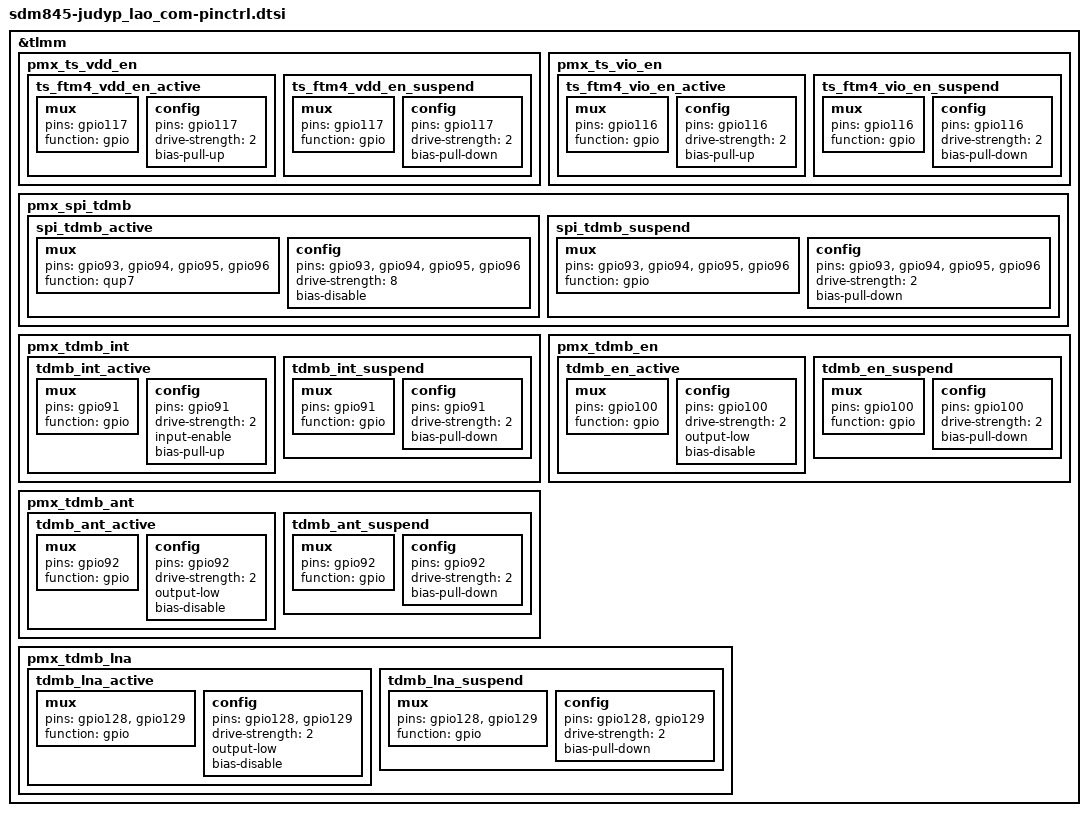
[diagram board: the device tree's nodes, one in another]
/* Copyright (c) 2017, The Linux Foundation. All rights reserved.
 *
 * This program is free software; you can redistribute it and/or modify
 * it under the terms of the GNU General Public License version 2 and
 * only version 2 as published by the Free Software Foundation.
 *
 * This program is distributed in the hope that it will be useful,
 * but WITHOUT ANY WARRANTY; without even the implied warranty of
 * MERCHANTABILITY or FITNESS FOR A PARTICULAR PURPOSE.  See the
 * GNU General Public License for more details.
 */

#include "../sdm845-judyp_common/sdm845-judyp_common-pinctrl.dtsi"

&tlmm {
	       pmx_ts_vdd_en {
			ts_ftm4_vdd_en_active: ts_ftm4_vdd_en_active {
				mux {
					pins = "gpio117";
					function = "gpio";
				};
				config {
					pins = "gpio117";
					drive-strength = <2>;
					bias-pull-up;
				};
			};

			ts_ftm4_vdd_en_suspend: ts_ftm4_vdd_en_suspend {
				mux {
					pins = "gpio117";
					function = "gpio";
				};
				config {
					pins = "gpio117";
					drive-strength = <2>;
					bias-pull-down;
				};
			};
		};

		pmx_ts_vio_en {
			ts_ftm4_vio_en_active: ts_ftm4_vio_en_active {
				mux {
					pins = "gpio116";
					function = "gpio";
				};
				config {
					pins = "gpio116";
					drive-strength = <2>;
					bias-pull-up;
				};
			};

			ts_ftm4_vio_en_suspend: ts_ftm4_vio_en_suspend {
				mux {
					pins = "gpio116";
					function = "gpio";
				};
				config {
					pins = "gpio116";
					drive-strength = <2>;
					bias-pull-down;
				};
			};
		};

	pmx_spi_tdmb {
		spi_tdmb_active: spi_tdmb_active {
			mux {
				pins =  "gpio93", "gpio94", "gpio95", "gpio96";
				function = "qup7";
			};

			config {
				pins =  "gpio93", "gpio94", "gpio95", "gpio96";
				drive-strength = <8>;
				bias-disable;
			};
		};

		spi_tdmb_suspend: spi_tdmb_suspend {
			mux {
				pins =  "gpio93", "gpio94", "gpio95", "gpio96";
				function = "gpio";
			};

			config {
				pins =  "gpio93", "gpio94", "gpio95", "gpio96";
				drive-strength = <2>;
				bias-pull-down;
			};
		};
	};

	pmx_tdmb_int {
		tdmb_int_active: tdmb_int_active {
			mux {
				pins = "gpio91";
				function = "gpio";
			};
			config {
				pins = "gpio91";
				drive-strength = <2>;
				input-enable;
				bias-pull-up;
			};
		};
		tdmb_int_suspend: tdmb_int_suspend {
			mux {
				pins = "gpio91";
				function = "gpio";
			};
			config {
				pins = "gpio91";
				drive-strength = <2>;
				bias-pull-down;
			};
		};

	};

	pmx_tdmb_en {
		tdmb_en_active: tdmb_en_active {
			mux {
				pins = "gpio100";
				function = "gpio";
			};
			config {
				pins = "gpio100";
				drive-strength = <2>;
				output-low;
				bias-disable;
			};
		};

		tdmb_en_suspend: tdmb_en_suspend {
			mux {
				pins = "gpio100";
				function = "gpio";
			};
			config {
				pins = "gpio100";
				drive-strength = <2>;
				bias-pull-down;
			};
		};

	};

	pmx_tdmb_ant {
		tdmb_ant_active: tdmb_ant_active {
			mux {
				pins = "gpio92";
				function = "gpio";
			};
			config {
				pins = "gpio92";
				drive-strength = <2>;
				output-low;
				bias-disable;
			};
		};

		tdmb_ant_suspend: tdmb_ant_suspend {
			mux {
				pins = "gpio92";
				function = "gpio";
			};
			config {
				pins = "gpio92";
				drive-strength = <2>;
				bias-pull-down;
			};
		};
	};

	pmx_tdmb_lna {
		tdmb_lna_active: tdmb_lna_active {
			mux {
				pins = "gpio128", "gpio129";
				function = "gpio";
			};
			config {
				pins = "gpio128", "gpio129";
				drive-strength = <2>;
				output-low;
				bias-disable;
			};
		};

		tdmb_lna_suspend: tdmb_lna_suspend {
			mux {
				pins = "gpio128", "gpio129";
				function = "gpio";
			};
			config {
				pins = "gpio128", "gpio129";
				drive-strength = <2>;
				bias-pull-down;
			};
		};
	};
};
